# ATA5835 device description
Architecture: AVR8; Family: megaAVR
Registers are 8-bit, access not given, no defined reset value unless marked. A register's access mark holds for its fields unless they carry their own. Offsets are from the block's base; [hi:lo] are bit positions.

## LIN_UART
Instances: LIN_UART 0x00
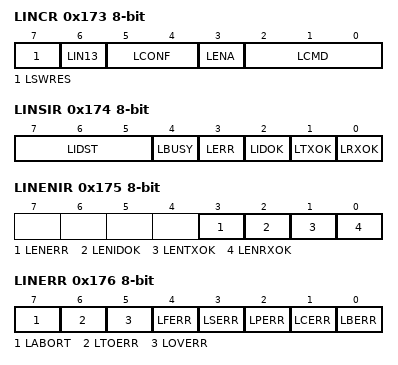
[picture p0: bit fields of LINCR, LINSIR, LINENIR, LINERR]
0x173 LINCR — LIN/UART Control Register
  [7] LSWRES — LIN/UART Software Reset
  [6] LIN13 — LIN 1.3 Mode
  [5:4] LCONF — LIN/UART Configuration
  [3] LENA — LIN/UART Enable
  [2:0] LCMD — LIN/UART Command and Mode
0x174 LINSIR — LIN Status and Interrupt Register
  [7:5] LIDST — LIN Identifier Status
  [4] LBUSY — LIN/UART Busy Flag
  [3] LERR — LIN/UART Error Flag
  [2] LIDOK — LIN Identifier Ok Flag
  [1] LTXOK — LIN/UART Transmit Ok Flag
  [0] LRXOK — LIN/UART Receive Ok Flag
0x175 LINENIR — LIN/UART Enable Interrupt Register
  [3] LENERR — LIN/UART Enable Error Interrupt
  [2] LENIDOK — LIN Enable Identifier Ok Interrupt
  [1] LENTXOK — LIN/UART Enable Transmit Ok Interrupt
  [0] LENRXOK — LIN/UART Enable Receive Ok Interrupt
0x176 LINERR — LIN/UART Error Register
  [7] LABORT — LIN Abort Flag
  [6] LTOERR — LIN Frame Time Out Error Flag
  [5] LOVERR — LIN/UART Overrun Error Flag
  [4] LFERR — LIN/UART Framing Error Flag
  [3] LSERR — LIN Synchronization Error Flag
  [2] LPERR — LIN Parity Error Flag
  [1] LCERR — LIN Checksum Error Flag
  [0] LBERR — LIN Bit Error Flag
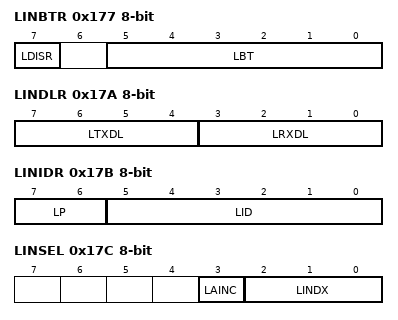
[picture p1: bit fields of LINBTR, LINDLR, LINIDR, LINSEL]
0x177 LINBTR — LIN/UART Bit Timing Register
  [7] LDISR — LIN/UART Disable Bit Timing Resynchronization
  [5:0] LBT — LIN/UART Bit Timing
0x178 LINBRRL — LIN/UART Baud Rate Register Low Byte
  [7:0] LDIV — LIN/UART Clock Divider
0x179 LINBRRH — LIN/UART Baud Rate Register High Byte
  [3:0] LDIV (bit 8 of the value upward) — LIN/UART Clock Divider
0x17A LINDLR — LIN/UART Data Length Register
  [7:4] LTXDL — LIN Transmit Data Length
  [3:0] LRXDL — LIN Receive Data Length
0x17B LINIDR — LIN/UART Identifier Register
  [7:6] LP — LIN Parity
  [5:0] LID — LIN Identifier
0x17C LINSEL — LIN/UART Data Buffer Selection
  [3] LAINC — LIN Auto Increment of Data Buffer Index Disable
  [2:0] LINDX — LIN Data Buffer Index
0x17D LINDAT — LIN/UART Data Register
  [7:0] LDATA — LIN/UART Data

## OCCOUNT
Instances: OCCOUNT 0x00
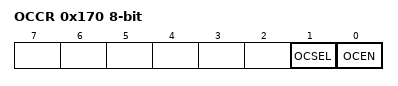
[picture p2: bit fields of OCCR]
0x170 OCCR — Oscillator Calibration Counter Configuration Register
  [1] OCSEL — Oscillator Calibration Select Target
  [0] OCEN — Oscillator Calibration Counter Enable
0x171 OCCNT — Oscillator Calibration Counter Value
0x172 OCGATE — Oscillator Calibration Counter Gate

## PORTB
Instances: PORTB 0x00
0x25 PINB — Port B Input Pins
0x26 DDRB — Port B Data Direction
0x27 PORTB — Port B Data Register

## PORTC
Instances: PORTC 0x00
0x28 PINC bits used 5:0 — Port C Input Pins
0x29 DDRC bits used 5:0 — Port C Data Direction
0x2A PORTC bits used 5:0 — Port C Data Register

## PORTS
Instances: PORTS 0x00
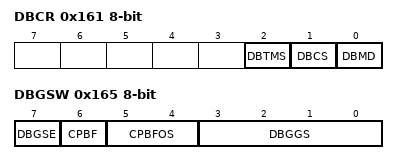
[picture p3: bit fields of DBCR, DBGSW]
0x161 DBCR — Debounce Control Register
  [2] DBTMS — Debounce Timer Mask Select
  [1] DBCS — Debounce Clock Select
  [0] DBMD — Debounce Mode
0x162 DBTC — Debounce Timer Compare
0x163 DBENB — Debounce Enable Port B
0x164 DBENC bits used 5:0 — Debounce Enable Port C
0x165 DBGSW — Debug Support Switch
  [7] DBGSE — Debug Support Switch Enable
  [6] CPBF — CPU Busy Flag
  [5:4] CPBFOS — CPU Busy Flag Output Select
    0=no output; 1=PB0; 2=PB4; 3=PC1
  [3:0] DBGGS — Debug Support Group Select

## RSSIB
Instances: RSSIB 0x00
0x15C RSSAV — RSSI Average Value
0x15D RSSPK — RSSI Peak Value
0x15E RSSL — RSSI Low Threshold
0x15F RSSH — RSSI High Threshold
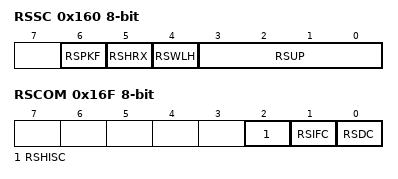
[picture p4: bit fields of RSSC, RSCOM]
0x160 RSSC — RSSI Configuration Register
  [6] RSPKF — RSSI Peak Values to SFIFO
  [5] RSHRX — RSSI High Band Reception
  [4] RSWLH — RSSI Within Low and High Limits
  [3:0] RSUP — RSSI Update Period
0x16B RSHSG — RSSI LNA High Sensitivity Gain
0x16C RSIFG — RSSI IF Amplifier Gain
0x16D RSLDV — RSSI Low Band Damping Value
0x16E RSHDV — RSSI High Band Damping Value
0x16F RSCOM — RSSI Compensation Register
  [2] RSHISC — RSSI LNA High Sensitivity Compensation
  [1] RSIFC — RSSI IF Amplifier Compensation
  [0] RSDC — RSSI Damping Compensation
